# f2838x_cla_softint_regs register map
Vendor: Texas Instruments
Peripheral module from a debugger description file (folder C2000).
Address unit: 16 bits
Registers are 16-bit, read-write, no defined reset value unless marked. A register's access mark holds for its fields unless they carry their own. Offsets are as the file gives them; lines under a group give offsets from that group; [hi:lo] are bit positions; {n}, {i} and the like mark numbered series; 'fields as' and 'values as' point back to an identical list; <NAME> marks a mode.

## CLA_SOFTINT_REGS — CLA SOFTINT Registers
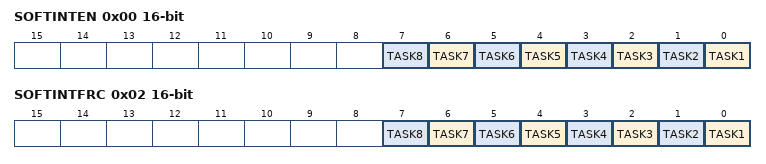
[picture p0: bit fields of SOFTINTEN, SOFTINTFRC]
0x00 SOFTINTEN — CLA Software Interrupt Enable Register
  [n-1] TASK{n} (n=1..8) — Configure Software Interrupt or End of Task interrupt.
0x02 SOFTINTFRC — CLA Software Interrupt Force Register
  [n-1] TASK{n} (n=1..8) — Force CLA software interrupt for the corresponding task.
